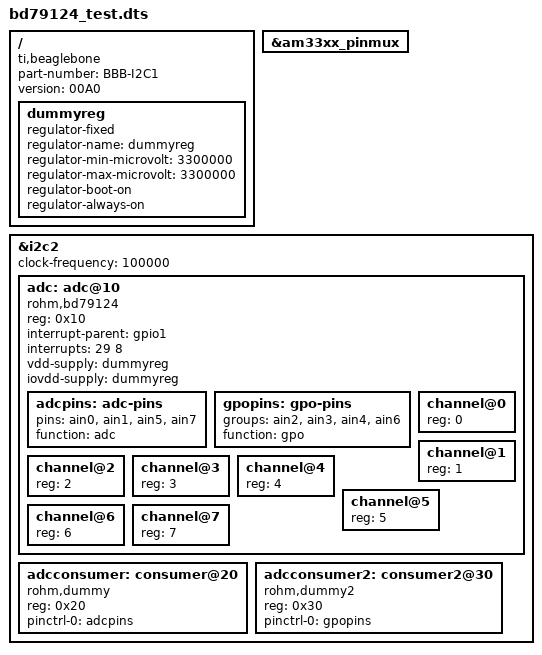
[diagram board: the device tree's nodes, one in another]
/dts-v1/;
/plugin/;

/{ /* this is our device tree overlay root node */

	compatible = "ti,beaglebone", "ti,beaglebone-black";
	part-number = "BBB-I2C1"; // you can choose any name here but it should be memorable
 	version = "00A0";

	fragment@0 {
		target = <&am33xx_pinmux>; 

		__overlay__ {
//			i2c2_pins: pinmux_i2c2_pins {
//				pinctrl-single,pins = <
				/* 0x158 - pin 17.
				   0x15C - pin 18
					0x72:
					b[2:0] = 2 => mux mode 2 (i2c1 p17/p18,SCL/SDA)
					b[3] = 0 => pullup/pulldown enabled
					b[4] = 1 => pull-up, not pull down
					b[5] = 1 => receiver active
					b[6] = 1 => slew control slow
				*/
//				0x17C 0x73 /* P9_19 (I2C-2 SCL) (input, pull-u, mode 3) */
//				0x178 0x73 /* P9_20 (I2C-2 SDA) (input, pull-u, mode 3)*/
          			/* 0x158 0x72   spi0_d1.i2c1_sda */ 
          			/* 0x15C 0x72  spi0_cs0.i2c1_sdl */
/*				0xA4 0x7    */ /* pin 46, GPIO 2_7 mode 7 */
/*				0xA0 0x7    */ /* pin 45, GPIO 2_6 mode 7 */
/*				0x0c 0x7    */ /* pin 3, GPIO 1_6 mode 7 */
/*				0x10 0x7    */ /* pin 4, GPIO 1_7 mode 7 */
//        			>;
		};
	};
	fragment@1 {
		target = <&i2c2>;

		__overlay__ {
//			pinctrl-0 = <&i2c2_pins>;
			clock-frequency = <100000>;
			status = "okay";

			adc: adc@10 { /* the "test" defined as child of the i2c1 bus */
				compatible = "rohm,bd79124";
				reg = <0x10>;
				/* GPIO 1_29 - (connector 8, pin 26) for irq */
				interrupt-parent = <&gpio1>;
/*				interrupts = <29 GPIO_ACTIVE_LOW>; */
				interrupts = <29 8>;
				vdd-supply = <&dummyreg>; 
				iovdd-supply = <&dummyreg>; 

				adcpins: adc-pins {
					pins = "ain0", "ain1", "ain5", "ain7";
					function = "adc";
				};
				gpopins: gpo-pins {
					groups = "ain2", "ain3", "ain4", "ain6";
					function = "gpo";
				};
				channel@0 {
					reg = <0>;
				};
				channel@1 {
					reg = <1>;
				};
				channel@2 {
					reg = <2>;
				};
				channel@3 {
					reg = <3>;
				};
				channel@4 {
					reg = <4>;
				};
				channel@5 {
					reg = <5>;
				};
				channel@6 {
					reg = <6>;
				};
				channel@7 {
					reg = <7>;
				};
			};
			adcconsumer: consumer@20 {
				reg = <0x20>;
				compatible = "rohm,dummy";
				pinctrl-names = "default";
				pinctrl-0 = <&adcpins>;
			};
			adcconsumer2: consumer2@30 {
				reg = <0x30>;
				compatible = "rohm,dummy2";
				pinctrl-names = "default";
				pinctrl-0 = <&gpopins>;
			};
		};
	};
	fragment@2 {
		target-path = "/";
		__overlay__ {
			dummyreg: dummyreg {
				compatible = "regulator-fixed";
				regulator-name = "dummyreg";
				regulator-min-microvolt = <3300000>;
				regulator-max-microvolt = <3300000>;
				regulator-boot-on;
				regulator-always-on;
			};
		};
	};

}; /* root node end */
